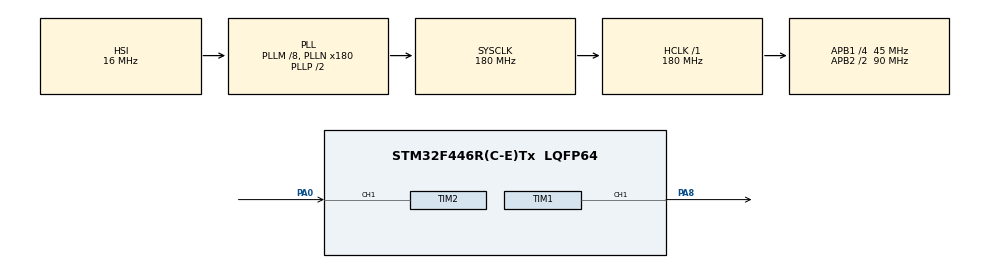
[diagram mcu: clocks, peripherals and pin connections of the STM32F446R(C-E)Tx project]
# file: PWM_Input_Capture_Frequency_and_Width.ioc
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Mcu.Family=STM32F4
Mcu.Name=STM32F446R(C-E)Tx
Mcu.Package=LQFP64
NVIC.PriorityGroup=NVIC_PRIORITYGROUP_4
NVIC.TIM2_IRQn=true\:0\:0\:false\:false\:true\:true\:true\:true
PA0-WKUP.Signal=S_TIM2_CH1_ETR
PA8.Signal=S_TIM1_CH1
PH0-OSC_IN.Mode=HSE-External-Oscillator
PH0-OSC_IN.Signal=RCC_OSC_IN
PH1-OSC_OUT.Mode=HSE-External-Oscillator
PH1-OSC_OUT.Signal=RCC_OSC_OUT
ProjectManager.HeapSize=0x200
ProjectManager.StackSize=0x400
ProjectManager.TargetToolchain=STM32CubeIDE
RCC.AHBFreq_Value=180000000
RCC.APB1CLKDivider=RCC_HCLK_DIV4
RCC.APB1Freq_Value=45000000
RCC.APB1TimFreq_Value=90000000
RCC.APB2CLKDivider=RCC_HCLK_DIV2
RCC.APB2Freq_Value=90000000
RCC.APB2TimFreq_Value=180000000
RCC.CortexFreq_Value=180000000
RCC.HCLKFreq_Value=180000000
RCC.HSE_VALUE=8000000
RCC.PLLM=8
RCC.PLLN=180
RCC.SYSCLKFreq_VALUE=180000000
RCC.SYSCLKSource=RCC_SYSCLKSOURCE_PLLCLK
RCC.USBFreq_Value=180000000
RCC.VCOOutputFreq_Value=360000000
SH.S_TIM1_CH1.0=TIM1_CH1,PWM Generation1 CH1
SH.S_TIM2_CH1_ETR.0=TIM2_CH1,Input_Capture1_from_TI1
TIM1.Channel-PWM\ Generation1\ CH1=TIM_CHANNEL_1
TIM1.Period=100
TIM1.Prescaler=180-1
TIM2.Channel-Input_Capture1_from_TI1=TIM_CHANNEL_1
TIM2.ICPrescaler-Input_Capture1_from_TI1=TIM_ICPSC_DIV1
TIM2.Prescaler=90-1
VP_TIM1_VS_ClockSourceINT.Mode=Internal
VP_TIM2_VS_ClockSourceINT.Mode=Internal
board=custom

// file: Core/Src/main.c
/* USER CODE BEGIN Header */
/**
  ******************************************************************************
  * @file           : main.c
  * @brief          : Main program body
  ******************************************************************************
  * @attention
  *
  * Copyright (c) 2025 STMicroelectronics.
  * All rights reserved.
  *
  * This software is licensed under terms that can be found in the LICENSE file
  * in the root directory of this software component.
  * If no LICENSE file comes with this software, it is provided AS-IS.
  *
  ******************************************************************************
  */
/* USER CODE END Header */
#include "main.h"

/* USER CODE BEGIN Includes */
#include <stdbool.h>

/* USER CODE END Includes */

TIM_HandleTypeDef htim1;
TIM_HandleTypeDef htim2;

void SystemClock_Config(void);
static void MX_GPIO_Init(void);
static void MX_TIM1_Init(void);
static void MX_TIM2_Init(void);

/* USER CODE BEGIN 0 */
#define TIMCLOCK 90000000 //The frequency of Timer2 connected to APB1 running at 90 MHz
#define PRESCALER 90

uint32_t IC_Value1 = 0;
uint32_t IC_Value2 = 0;
uint32_t Difference = 0;
bool is_First_Captured = false;

float frequency = 0;
float refClock = 0; //Reference clock
float width = 0;
float mFactor = 0;

//Measure frequency
/*
void HAL_TIM_IC_CaptureCallback(TIM_HandleTypeDef *htim)
{
	if (htim->Channel == HAL_TIM_ACTIVE_CHANNEL_1)
	{
		if (is_First_Captured == false)
		{
			IC_Value1 = HAL_TIM_ReadCapturedValue(htim, TIM_CHANNEL_1); //Reading the 1st value
			is_First_Captured = true;
		}

		else //If the 1st rising edge was captured previously
		{
			IC_Value2 = HAL_TIM_ReadCapturedValue(htim, TIM_CHANNEL_1); //Reading the 2nd value

			if (IC_Value2 > IC_Value1)
			{
				Difference = IC_Value2 - IC_Value1;
			}
			else if (IC_Value1 > IC_Value2)
			{
				Difference = (0xffffffff - IC_Value1) + IC_Value2;
			}

			refClock = TIMCLOCK / PRESCALER;
			frequency = refClock / Difference;
			__HAL_TIM_SET_COUNTER(htim, 0); //Reset the counter
			is_First_Captured = false;
		}
	}
}
*/
//-------------------------------------------------------------------------------------
//Measure width
void HAL_TIM_IC_CaptureCallback(TIM_HandleTypeDef *htim)
{
	if (htim->Channel == HAL_TIM_ACTIVE_CHANNEL_1)
	{
		if (is_First_Captured == false)
		{
			IC_Value1 = HAL_TIM_ReadCapturedValue(htim, TIM_CHANNEL_1); //Reading the 1st value
			is_First_Captured = true;
		}

		else //If the 1st rising edge was captured previously
		{
			IC_Value2 = HAL_TIM_ReadCapturedValue(htim, TIM_CHANNEL_1); //Reading the 2nd value

			if (IC_Value2 > IC_Value1)
			{
				Difference = IC_Value2 - IC_Value1;
			}
			else if (IC_Value1 > IC_Value2)
			{
				Difference = (0xffffffff - IC_Value1) + IC_Value2;
			}

			refClock = TIMCLOCK / PRESCALER;

			mFactor = 1000000 / refClock;
			width = Difference * mFactor; //The width of the signal in microseconds

			__HAL_TIM_SET_COUNTER(htim, 0); //Reset the counter
			is_First_Captured = false;
		}
	}
}
//-----------------------------------------------------------------------------------------
/* USER CODE END 0 */

int main(void)
{

  /* MCU Configuration--------------------------------------------------------*/

  /* Reset of all peripherals, Initializes the Flash interface and the Systick. */
  HAL_Init();

  /* Configure the system clock */
  SystemClock_Config();

  /* Initialize all configured peripherals */
  MX_GPIO_Init();
  MX_TIM1_Init();
  MX_TIM2_Init();
  /* USER CODE BEGIN 2 */

  TIM1->CCR1 = 50;
  HAL_TIM_PWM_Start(&htim1, TIM_CHANNEL_1); //Start Fast PWM

  HAL_TIM_IC_Start_IT(&htim2, TIM_CHANNEL_1); //Start Input Capture in the Interrupt mode

  /* USER CODE END 2 */

  /* Infinite loop */
  while (1)
  {

  }
}

void SystemClock_Config(void)
{
  RCC_OscInitTypeDef RCC_OscInitStruct = {0};
  RCC_ClkInitTypeDef RCC_ClkInitStruct = {0};

  /** Configure the main internal regulator output voltage
  */
  __HAL_RCC_PWR_CLK_ENABLE();
  __HAL_PWR_VOLTAGESCALING_CONFIG(PWR_REGULATOR_VOLTAGE_SCALE1);

  /** Initializes the RCC Oscillators according to the specified parameters
  * in the RCC_OscInitTypeDef structure.
  */
  RCC_OscInitStruct.OscillatorType = RCC_OSCILLATORTYPE_HSI;
  RCC_OscInitStruct.HSIState = RCC_HSI_ON;
  RCC_OscInitStruct.HSICalibrationValue = RCC_HSICALIBRATION_DEFAULT;
  RCC_OscInitStruct.PLL.PLLState = RCC_PLL_ON;
  RCC_OscInitStruct.PLL.PLLSource = RCC_PLLSOURCE_HSI;
  RCC_OscInitStruct.PLL.PLLM = 8;
  RCC_OscInitStruct.PLL.PLLN = 180;
  RCC_OscInitStruct.PLL.PLLP = RCC_PLLP_DIV2;
  RCC_OscInitStruct.PLL.PLLQ = 2;
  RCC_OscInitStruct.PLL.PLLR = 2;
  if (HAL_RCC_OscConfig(&RCC_OscInitStruct) != HAL_OK)
  {
    Error_Handler();
  }

  /** Activate the Over-Drive mode
  */
  if (HAL_PWREx_EnableOverDrive() != HAL_OK)
  {
    Error_Handler();
  }

  /** Initializes the CPU, AHB and APB buses clocks
  */
  RCC_ClkInitStruct.ClockType = RCC_CLOCKTYPE_HCLK|RCC_CLOCKTYPE_SYSCLK
                              |RCC_CLOCKTYPE_PCLK1|RCC_CLOCKTYPE_PCLK2;
  RCC_ClkInitStruct.SYSCLKSource = RCC_SYSCLKSOURCE_PLLCLK;
  RCC_ClkInitStruct.AHBCLKDivider = RCC_SYSCLK_DIV1;
  RCC_ClkInitStruct.APB1CLKDivider = RCC_HCLK_DIV4;
  RCC_ClkInitStruct.APB2CLKDivider = RCC_HCLK_DIV2;

  if (HAL_RCC_ClockConfig(&RCC_ClkInitStruct, FLASH_LATENCY_5) != HAL_OK)
  {
    Error_Handler();
  }
}

static void MX_TIM1_Init(void)
{

  TIM_ClockConfigTypeDef sClockSourceConfig = {0};
  TIM_MasterConfigTypeDef sMasterConfig = {0};
  TIM_OC_InitTypeDef sConfigOC = {0};
  TIM_BreakDeadTimeConfigTypeDef sBreakDeadTimeConfig = {0};

  htim1.Instance = TIM1;
  htim1.Init.Prescaler = 180-1; //The prescaler defines what frequency the timer will be running at. It always should be one less than the required value.
  htim1.Init.CounterMode = TIM_COUNTERMODE_UP;
  htim1.Init.Period = 100; //The counter counts to 100 and then resets
  htim1.Init.ClockDivision = TIM_CLOCKDIVISION_DIV1;
  htim1.Init.RepetitionCounter = 0;
  htim1.Init.AutoReloadPreload = TIM_AUTORELOAD_PRELOAD_DISABLE;
  if (HAL_TIM_Base_Init(&htim1) != HAL_OK)
  {
    Error_Handler();
  }
  sClockSourceConfig.ClockSource = TIM_CLOCKSOURCE_INTERNAL;
  if (HAL_TIM_ConfigClockSource(&htim1, &sClockSourceConfig) != HAL_OK)
  {
    Error_Handler();
  }
  if (HAL_TIM_PWM_Init(&htim1) != HAL_OK)
  {
    Error_Handler();
  }
  sMasterConfig.MasterOutputTrigger = TIM_TRGO_RESET;
  sMasterConfig.MasterSlaveMode = TIM_MASTERSLAVEMODE_DISABLE;
  if (HAL_TIMEx_MasterConfigSynchronization(&htim1, &sMasterConfig) != HAL_OK)
  {
    Error_Handler();
  }
  sConfigOC.OCMode = TIM_OCMODE_PWM1;
  sConfigOC.Pulse = 0;
  sConfigOC.OCPolarity = TIM_OCPOLARITY_HIGH;
  sConfigOC.OCNPolarity = TIM_OCNPOLARITY_HIGH;
  sConfigOC.OCFastMode = TIM_OCFAST_DISABLE;
  sConfigOC.OCIdleState = TIM_OCIDLESTATE_RESET;
  sConfigOC.OCNIdleState = TIM_OCNIDLESTATE_RESET;
  if (HAL_TIM_PWM_ConfigChannel(&htim1, &sConfigOC, TIM_CHANNEL_1) != HAL_OK)
  {
    Error_Handler();
  }
  sBreakDeadTimeConfig.OffStateRunMode = TIM_OSSR_DISABLE;
  sBreakDeadTimeConfig.OffStateIDLEMode = TIM_OSSI_DISABLE;
  sBreakDeadTimeConfig.LockLevel = TIM_LOCKLEVEL_OFF;
  sBreakDeadTimeConfig.DeadTime = 0;
  sBreakDeadTimeConfig.BreakState = TIM_BREAK_DISABLE;
  sBreakDeadTimeConfig.BreakPolarity = TIM_BREAKPOLARITY_HIGH;
  sBreakDeadTimeConfig.AutomaticOutput = TIM_AUTOMATICOUTPUT_DISABLE;
  if (HAL_TIMEx_ConfigBreakDeadTime(&htim1, &sBreakDeadTimeConfig) != HAL_OK)
  {
    Error_Handler();
  }
  HAL_TIM_MspPostInit(&htim1);

}

static void MX_TIM2_Init(void)
{

  TIM_ClockConfigTypeDef sClockSourceConfig = {0};
  TIM_MasterConfigTypeDef sMasterConfig = {0};
  TIM_IC_InitTypeDef sConfigIC = {0};

  htim2.Instance = TIM2;
  htim2.Init.Prescaler = 90-1;
  htim2.Init.CounterMode = TIM_COUNTERMODE_UP;
  htim2.Init.Period = 4294967295;
  htim2.Init.ClockDivision = TIM_CLOCKDIVISION_DIV1;
  htim2.Init.AutoReloadPreload = TIM_AUTORELOAD_PRELOAD_DISABLE;
  if (HAL_TIM_Base_Init(&htim2) != HAL_OK)
  {
    Error_Handler();
  }
  sClockSourceConfig.ClockSource = TIM_CLOCKSOURCE_INTERNAL;
  if (HAL_TIM_ConfigClockSource(&htim2, &sClockSourceConfig) != HAL_OK)
  {
    Error_Handler();
  }
  if (HAL_TIM_IC_Init(&htim2) != HAL_OK)
  {
    Error_Handler();
  }
  sMasterConfig.MasterOutputTrigger = TIM_TRGO_RESET;
  sMasterConfig.MasterSlaveMode = TIM_MASTERSLAVEMODE_DISABLE;
  if (HAL_TIMEx_MasterConfigSynchronization(&htim2, &sMasterConfig) != HAL_OK)
  {
    Error_Handler();
  }
  sConfigIC.ICPolarity = TIM_INPUTCHANNELPOLARITY_BOTHEDGE; //For measuring the width we need an interrupt at both rising and falling edges
                                                            //For measuring the frequency we need an interrupt only at rising edges
  sConfigIC.ICSelection = TIM_ICSELECTION_DIRECTTI;
  sConfigIC.ICPrescaler = TIM_ICPSC_DIV1;
  sConfigIC.ICFilter = 0;
  if (HAL_TIM_IC_ConfigChannel(&htim2, &sConfigIC, TIM_CHANNEL_1) != HAL_OK)
  {
    Error_Handler();
  }

}

static void MX_GPIO_Init(void)
{

  /* GPIO Ports Clock Enable */
  __HAL_RCC_GPIOH_CLK_ENABLE();
  __HAL_RCC_GPIOA_CLK_ENABLE();

}

void Error_Handler(void)
{
  __disable_irq();
  while (1)
  {
  }
}
